# DSS_EDP0_INTG_CFG_VP register map
Vendor: Texas Instruments
Peripheral module from a debugger description file (folder J721S2).
Registers are 32-bit, read-write, reset 0x0 unless marked. A register's access mark holds for its fields unless they carry their own. Offsets are as the file gives them; lines under a group give offsets from that group; [hi:lo] are bit positions; {n}, {i} and the like mark numbered series; 'fields as' and 'values as' point back to an identical list; <NAME> marks a mode.

## DSS_EDP0_INTG_CFG_VP
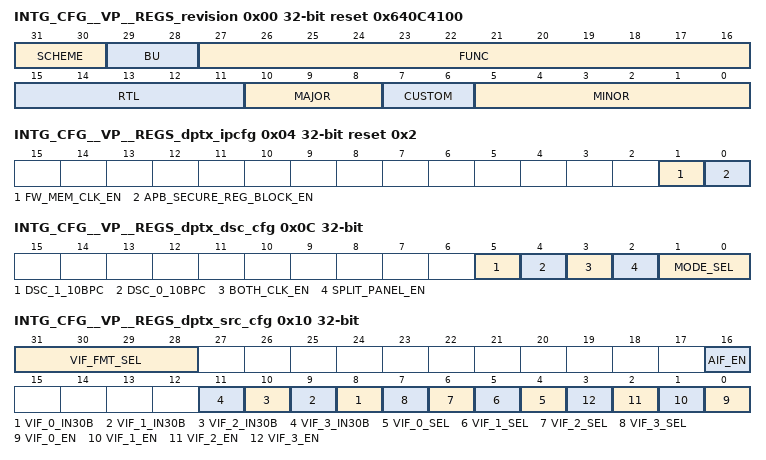
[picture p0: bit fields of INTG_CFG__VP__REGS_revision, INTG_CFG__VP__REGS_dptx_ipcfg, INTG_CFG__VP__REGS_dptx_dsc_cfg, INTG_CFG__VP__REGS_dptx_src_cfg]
0x00 INTG_CFG__VP__REGS_revision ro reset 0x640C4100 — The REVISION Register contains the major and minor revisions for the VPAC dptx HWA module.
  [31:30] SCHEME — Used to distinguish between old scheme and new scheme. Spare bit to encode future schemes
  [29:28] BU — BU indicator DSPS ==> 0x0 WTBU ==> 0x1 Processors ==> 0x2
  [27:16] FUNC — Function indicates a software compatible module family. If there is no level of software compatibility a new FUNC number, and hence PID, should be assigned.
  [15:11] RTL — RTL Version. R as described in PDR with additional clarifications and definitions below. Must be easily ECO-able or controlled during fabrication. Ideally through a top level metal mask or e-fuse. This number is maintained/owned by IP design owner. RTL follows a numbering such as X.Y.R.Z which are explained in this table. R changes ONLY when : (1) PDS uploads occur which may have been due to spec changes (2) Bug fixes occur (3) Resets to '0' when X or Y changes. Design team has an internal 'Z' (customer invisible) number which increments on every drop that happens due to DV and RTL updates. Z resets to 0 when R increments.
  [10:8] MAJOR — Major Revision. X as described in PDR with additional clarifications/definitions below. This number is owned/maintained by IP specification owner. X is part of IP numbering X.Y.R.Z. X changes ONLY when: (1) There is a major feature addition. An example would be adding Master Mode to Utopia Level2. The Func field (or Class/Type in old PID format) will remain the same. X does NOT change due to: (1) Bug fixes (2) Change in feature parameters.
  [7:6] CUSTOM — Indicates a special version for a particular device. Consequence of use may avoid use of standard Chip Support Library (CSL) / Drivers. 0 if non-c ustom.
  [5:0] MINOR — Minor Revision. Y as described in PDR with additional clarifications/definitions below. This number is owned/maintained by IP specification owne r. Y changes ONLY when: (1) Features are scaled (up or down). Flexibility exists in that this feature scalability may either be represented in the Y change or a specific register in the IP that indica tes which features are exactly available. (2) When feature creeps from Is-Not list to Is list. But this may not be the case once it sees silicon - in which case X will change. Y does NOT change due to : (1) Bug fixes (2) Typos or clarifications (3) major functional/feature change/addition/deletion. Instead these changes may be reflected via R, S, X as applicable. Spec owner maintains a customer-invisible number 'S' which changes due to: (1) Typos/clarifications (2) Bug documentation. Note that this bug is not due to a spec change but due to implementation. Nevertheless, the spec tracks the I P bugs. An RTL release (say for silicon PG1.1) that occurs due to bug fix should document the corresponding spec number (X.Y.S) in its release notes.
0x04 INTG_CFG__VP__REGS_dptx_ipcfg reset 0x2 — The DPTX_IPCFG Register - Configures DPTX Core security mode and fw memory clock enable.
  [1] FW_MEM_CLK_EN — DPTX firmware memory (I/Dram) clock enable (set to 1 by default after a reset) 0: Disable Clock (can be set to 0 when not in use for power saving) 1: Enable Clock (must for normal operation)
  [0] APB_SECURE_REG_BLOCK_EN — DPTX - APB secure region access block enable mode 0: Not Enabled (full access to DPTX memory space including uCPU FW memory regions are permitted) 1: Enabled (only Mailbox and non-secure APB region accesses are permitted via APB) On reset, this bit is set 0 to allow FW to be loaded during the initial configuration. To prevent any tempering of the FW and other secure regions, this bit should be set to 1 (if the configuration firewall setting allows access by a non-secure host) to limit the access only to the mailbox and general cfg space by APB accesses
0x08 INTG_CFG__VP__REGS_ecc_mem_cfg — The ECC_MEM_CFG Register - Enables clocks to the ECC-aggregator/memories for ECC logic access. The setting of 1 forces the functional clock gating to be bypassed during memory ECC CTRL/Aggregator accesses during ECC diagnostic mode.
  [0] CLK_EN — Clk Force Enable for ECC access 0: Disable 1: Enable (all clock gatings for the ECC memories/aggregator are bypassed) PHY/IO clocks may not be running during the ECC access. These clocks will still be off even when this parameter is set to 1
0x0C INTG_CFG__VP__REGS_dptx_dsc_cfg — The DPTX_DSC_CFG Register - Configures DSC usaged of the DPTX Core. The settings are used by the wrapper to control the source clock gating for DSC sub-module and also to force enable vif memory clocks as necessary.
  [5] DSC_1_10BPC — DPTX - DSC encoder 1 - 10-bit input enable 0: 8-bit (default) 1: 10-bit This setting must match the DSC_ENC1 input_bpc[0] configuration
  [4] DSC_0_10BPC — DPTX - DSC encoder 0 - 10-bit input enable 0: 8-bit (default) 1: 10-bit This setting must match the DSC_ENC0 input_bpc[0] configuration
  [3] BOTH_CLK_EN — DPTX - DSC force both clock on whenever DSC is active 0: Disabled (Normal setting - DSC clock enable is controlled based on mode_sel) 1: Enabled (Reserved)
  [2] SPLIT_PANEL_EN — DPTX - DSC encoder mode select 0: Dual Panel (two independent streams) 1: Split Panel (L/R channels of a single source In Split Panel mode, the selected vif_0 and vif_1 stream must be video timing synchronized. Both split/dual panel modes require clocks to be in sync/phase.)
  [1:0] MODE_SEL — DPTX - DSC encoder mode select 2'b00: Both encoders Disabled (not used) 2'b01: Single Encoder (only enc0 is used) 2'b11: Both Encoders Enabled When both Encoders are enabled, it can either be in split panel or dual panel mode
0x10 INTG_CFG__VP__REGS_dptx_src_cfg — The DPTX_SRC_CFG Register - Configures VIF and AIF port channel enables (for memory clock gating) and VIF source mux selection (for mapping DPI to VIF ports). The VIF_#_en also enables the clock for the # channel PIF memory. If a PIF channel is enabled, the vif_#_en must be set regardless of whether the associated video channel has the video enabled or not. Note that these settings are only used in the K3_DSS_eDP wrapper level (for controlling the memory clocks). The DPTX core requires separate configuration for enabling the video/audio streams for transmission. The enable settings between the core and wrapper should match for proper operation.
  [31:28] VIF_FMT_SEL — Reserved - must be set to 0
  [16] AIF_EN — DPTX Audio I2S channel memory clk enable 0 : Disable 1: Enable
  [n+8] VIF_{n}_IN30B (n=0..3) — DPTX vif_{n} source data width is 30 bits 0: 36 bits (default) 1: 30 bits
  [n+4] VIF_{n}_SEL (n=0..3) — DPTX vif_{n} source select - between dpi_{n} or dpi_{n+2} 0: dpi_{n} 1: dpi_{n+2}
  [n] VIF_{n}_EN (n=0..3) — DPTX vif_{n} channel memory clk enable 0: Disable 1: Enable
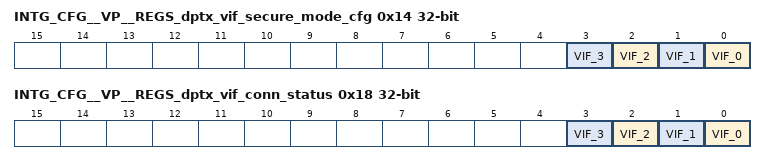
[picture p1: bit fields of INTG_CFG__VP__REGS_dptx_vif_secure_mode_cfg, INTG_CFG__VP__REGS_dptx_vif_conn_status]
0x14 INTG_CFG__VP__REGS_dptx_vif_secure_mode_cfg — The DPTX_VIF_SECURE_MODE_CFG Register - Configures the security level of the VIF channel (for protecting secure content from going to a non-protected display interface). When a VIF channel is configured as non-secure, the K3_DSS_eDP wrapper prevents secure DPI source data to be mapped to the VIF input. When this condition is detected, the wrapper forces the VIF source input to be 0x0. Therefore, if the DPI source from DSS is secure, then the mapped VIF channel must also be configured as secure.
  [n] VIF_{n} (n=0..3) — vif_{n} channel secure mode: 0: Non-Secure 1: Secure
0x18 INTG_CFG__VP__REGS_dptx_vif_conn_status ro — The DPTX_VIF_CONN_STATUS Register - Returns the status of DPI-VIF connection based on the security mode check. 0 indicates that the connection is allowed 1 indicates that the connection is not allowed due to security setting mismatch When a security mode mismatch is found on a VIF input channel, the source data signals for the channel are forced to 0 - resulting in black color output
  [n] VIF_{n} (n=0..3) — vif_0 security check status: 0: Conn Allowed - no security issue 1: Connection Not Allowed due to security mismatch
0x1C INTG_CFG__VP__REGS_phy_clk_status ro — The PHY_CLK_STATUS Register - Returns the current status of the phy data clock from DP phy. When the clock is not running, the ECC_aggr_PHY_cfg_regs will return 0x0 on a read
  [0] VALID — Phy Data Clock Valid Status 0: Clock is not valid/not running 1: Clock is running
